# STM32G07x register map
File version: 1.3
CPU: CM0+ r0p0, little endian, no MPU, no FPU, 3 interrupt priority bits
Registers are 32-bit, read-write, reset 0x0 unless marked. A register's access mark holds for its fields unless they carry their own. Offsets are from the block's base; [hi:lo] are bit positions; {n}, {i} and the like mark numbered series.

## LPUART — Universal synchronous asynchronous receiver transmitter
Base 0x40008000
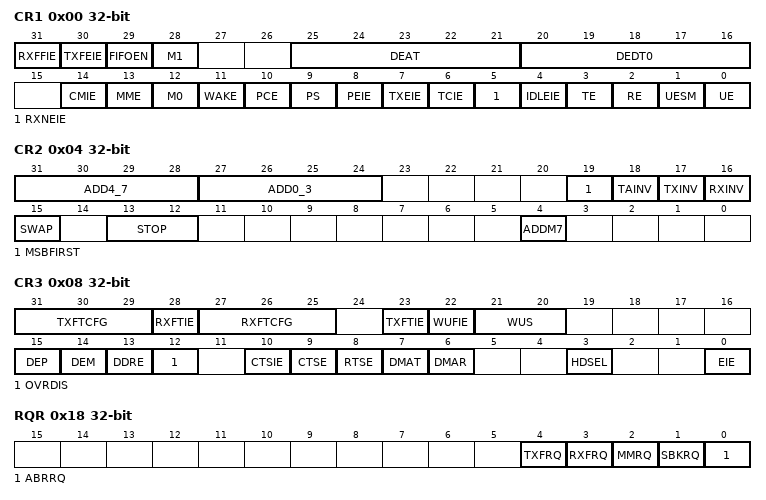
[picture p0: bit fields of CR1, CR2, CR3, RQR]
0x00 CR1 — Control register 1
  [31] RXFFIE — RXFIFO Full interrupt enable
  [30] TXFEIE — TXFIFO empty interrupt enable
  [29] FIFOEN — FIFO mode enable
  [28] M1 — Word length
  [25:21] DEAT — DEAT0
  [20:16] DEDT0
  [14] CMIE — Character match interrupt enable
  [13] MME — Mute mode enable
  [12] M0 — Word length
  [11] WAKE — Receiver wakeup method
  [10] PCE — Parity control enable
  [9] PS — Parity selection
  [8] PEIE — PE interrupt enable
  [7] TXEIE — interrupt enable
  [6] TCIE — Transmission complete interrupt enable
  [5] RXNEIE — RXNE interrupt enable
  [4] IDLEIE — IDLE interrupt enable
  [3] TE — Transmitter enable
  [2] RE — Receiver enable
  [1] UESM — USART enable in Stop mode
  [0] UE — USART enable
0x04 CR2 — Control register 2
  [31:28] ADD4_7 — Address of the USART node
  [27:24] ADD0_3 — Address of the USART node
  [19] MSBFIRST — Most significant bit first
  [18] TAINV — Binary data inversion
  [17] TXINV — TX pin active level inversion
  [16] RXINV — RX pin active level inversion
  [15] SWAP — Swap TX/RX pins
  [13:12] STOP — STOP bits
  [4] ADDM7 — 7-bit Address Detection/4-bit Address Detection
0x08 CR3 — Control register 3
  [31:29] TXFTCFG — TXFIFO threshold configuration
  [28] RXFTIE — RXFIFO threshold interrupt enable
  [27:25] RXFTCFG — Receive FIFO threshold configuration
  [23] TXFTIE — threshold interrupt enable
  [22] WUFIE — Wakeup from Stop mode interrupt enable
  [21:20] WUS — Wakeup from Stop mode interrupt flag selection
  [15] DEP — Driver enable polarity selection
  [14] DEM — Driver enable mode
  [13] DDRE — DMA Disable on Reception Error
  [12] OVRDIS — Overrun Disable
  [10] CTSIE — CTS interrupt enable
  [9] CTSE — CTS enable
  [8] RTSE — RTS enable
  [7] DMAT — DMA enable transmitter
  [6] DMAR — DMA enable receiver
  [3] HDSEL — Half-duplex selection
  [0] EIE — Error interrupt enable
0x0C BRR — Baud rate register
  [19:0] BRR
0x18 RQR wo — Request register
  [4] TXFRQ — Transmit data flush request
  [3] RXFRQ — Receive data flush request
  [2] MMRQ — Mute mode request
  [1] SBKRQ — Send break request
  [0] ABRRQ — Auto baud rate request
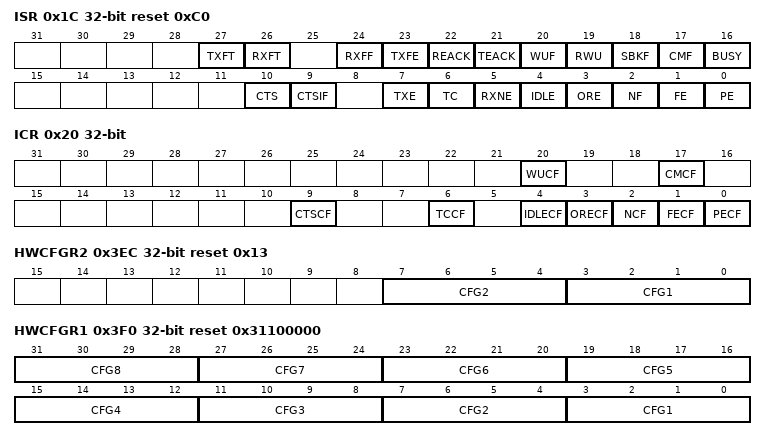
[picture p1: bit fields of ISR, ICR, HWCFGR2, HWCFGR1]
0x1C ISR ro reset 0xC0 — Interrupt & status register
  [27] TXFT — TXFIFO threshold flag
  [26] RXFT — RXFIFO threshold flag
  [24] RXFF — RXFIFO Full
  [23] TXFE — TXFIFO Empty
  [22] REACK
  [21] TEACK
  [20] WUF
  [19] RWU
  [18] SBKF
  [17] CMF
  [16] BUSY
  [10] CTS
  [9] CTSIF
  [7] TXE
  [6] TC
  [5] RXNE
  [4] IDLE
  [3] ORE
  [2] NF
  [1] FE
  [0] PE
0x20 ICR wo — Interrupt flag clear register
  [20] WUCF — Wakeup from Stop mode clear flag
  [17] CMCF — Character match clear flag
  [9] CTSCF — CTS clear flag
  [6] TCCF — Transmission complete clear flag
  [4] IDLECF — Idle line detected clear flag
  [3] ORECF — Overrun error clear flag
  [2] NCF — Noise detected clear flag
  [1] FECF — Framing error clear flag
  [0] PECF — Parity error clear flag
0x24 RDR ro — Receive data register
  [8:0] RDR — Receive data value
0x28 TDR — Transmit data register
  [8:0] TDR — Transmit data value
0x2C PRESC — Prescaler register
  [3:0] PRESCALER — Clock prescaler
0x3EC HWCFGR2 reset 0x13 — LPUART Hardware Configuration register 2
  [7:4] CFG2 — LUART hardware configuration 2
  [3:0] CFG1 — LUART hardware configuration 1
0x3F0 HWCFGR1 reset 0x31100000 — LPUART Hardware Configuration register 1
  [4n-1:4n-4] CFG{n} (n=4..8) — LUART hardware configuration 2
  [11:8] CFG3 — LUART hardware configuration 1
  [7:4] CFG2 — LUART hardware configuration 2
  [3:0] CFG1 — LUART hardware configuration 1
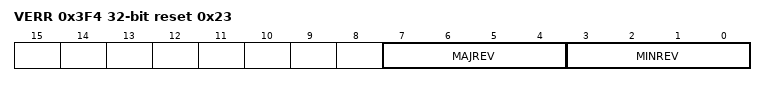
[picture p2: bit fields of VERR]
0x3F4 VERR ro reset 0x23 — EXTI IP Version register
  [7:4] MAJREV — Major Revision number
  [3:0] MINREV — Minor Revision number
0x3F8 IPIDR ro reset 0x130003 — EXTI Identification register
  [31:0] IPID — IP Identification
0x3FC SIDR ro reset 0xA3C5DD01 — EXTI Size ID register
  [31:0] SID — Size Identification
